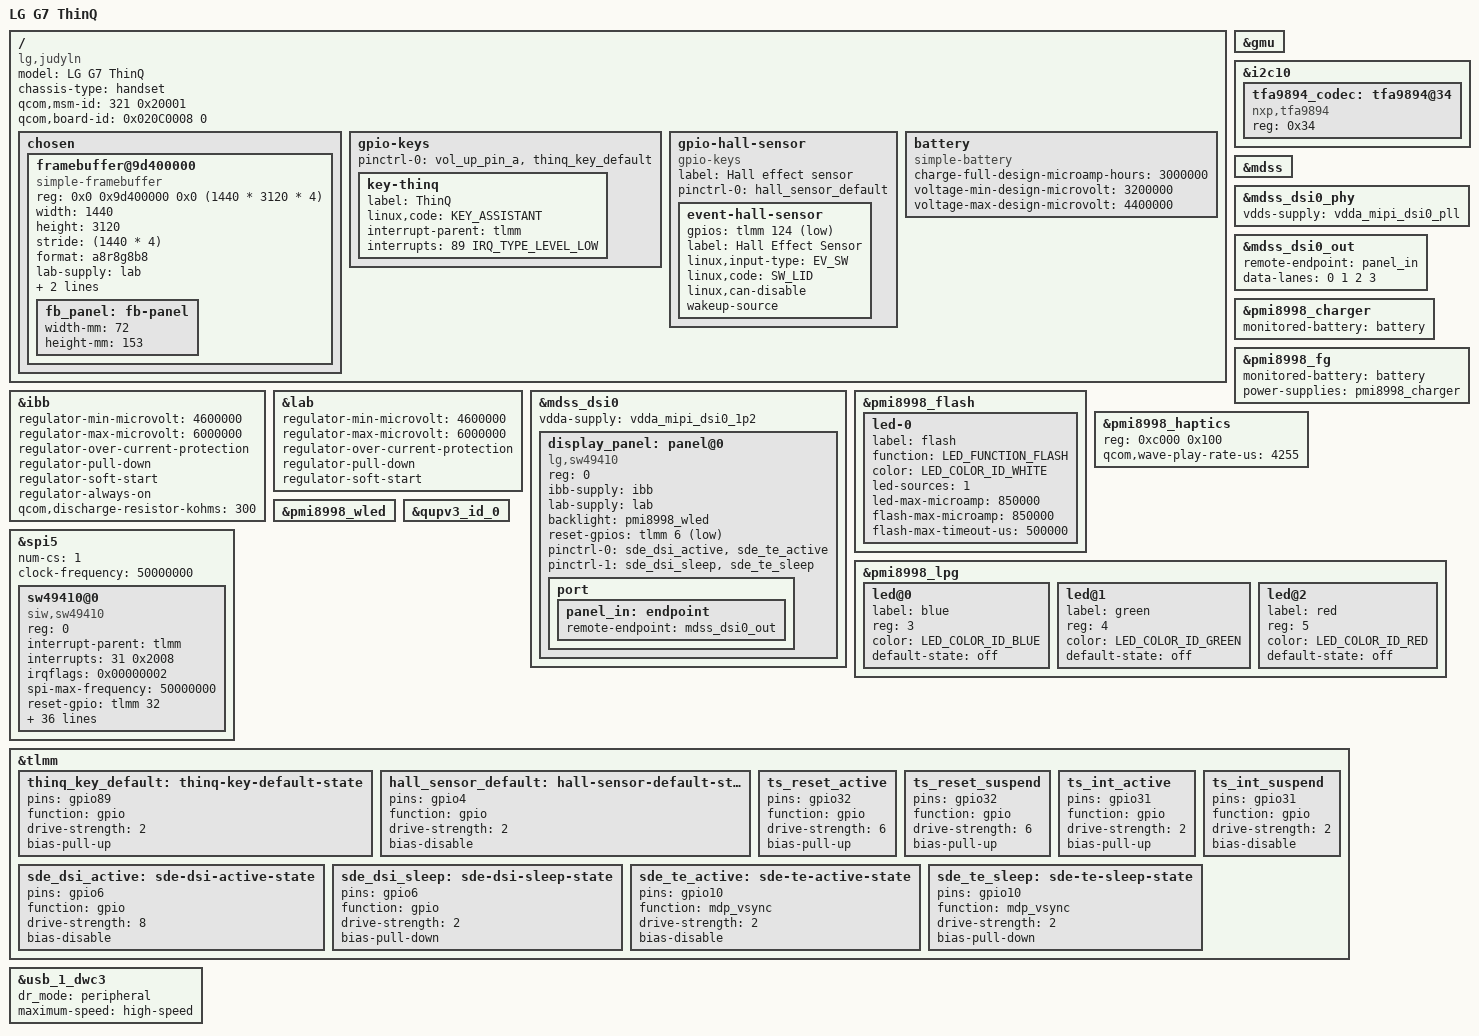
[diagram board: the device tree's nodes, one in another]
// SPDX-License-Identifier: GPL-2.0
/*
 * SDM845 LG G7 (judyln) device tree.
 *
 * Copyright (c) 2022, The Linux Foundation. All rights reserved.
 */

/dts-v1/;

#include "sdm845-lg-common.dtsi"
#include <dt-bindings/leds/common.h>

/ {
	model = "LG G7 ThinQ";
	compatible = "lg,judyln", "qcom,sdm845";
	chassis-type = "handset";
	qcom,msm-id = <321 0x20001>;
	qcom,board-id = <0x020C0008 0>;

	chosen {
		framebuffer@9d400000 {
			compatible = "simple-framebuffer";
			reg = <0x0 0x9d400000 0x0 (1440 * 3120 * 4)>;
			width = <1440>;
			height = <3120>;
			stride = <(1440 * 4)>;
			format = "a8r8g8b8";
			lab-supply = <&lab>;
			ibb-supply = <&ibb>;

			panel = <&fb_panel>;

			fb_panel: fb-panel {
				width-mm = <72>;
				height-mm = <153>;
			};
		};
	};

	/* Additional ThinQ key */
	gpio-keys {
		pinctrl-0 = <&vol_up_pin_a &thinq_key_default>;

		key-thinq {
			label = "ThinQ";
			linux,code = <KEY_ASSISTANT>;
			interrupt-parent = <&tlmm>;
			interrupts = <89 IRQ_TYPE_LEVEL_LOW>;
		};
	};

	gpio-hall-sensor {
		compatible = "gpio-keys";
		label = "Hall effect sensor";

		pinctrl-0 = <&hall_sensor_default>;
		pinctrl-names = "default";

		event-hall-sensor {
			gpios = <&tlmm 124 GPIO_ACTIVE_LOW>;
			label = "Hall Effect Sensor";
			linux,input-type = <EV_SW>;
			linux,code = <SW_LID>;
			linux,can-disable;
			wakeup-source;
		};
	};

	battery: battery {
		status = "okay";
		compatible = "simple-battery";

		charge-full-design-microamp-hours = <3000000>;
		voltage-min-design-microvolt = <3200000>;
		voltage-max-design-microvolt = <4400000>;
	};
};

&gmu {
	status = "okay";
};

&i2c10 {
	status = "okay";

	tfa9894_codec: tfa9894@34 {
		#sound-dai-cells = <1>;
		compatible = "nxp,tfa9894";
		reg = <0x34>;
	};
};

&ibb {
	regulator-min-microvolt = <4600000>;
	regulator-max-microvolt = <6000000>;
	regulator-over-current-protection;
	regulator-pull-down;
	regulator-soft-start;
	regulator-always-on;
	qcom,discharge-resistor-kohms = <300>;
};

&lab {
	regulator-min-microvolt = <4600000>;
	regulator-max-microvolt = <6000000>;
	regulator-over-current-protection;
	regulator-pull-down;
	regulator-soft-start;
};

&mdss {
	status = "okay";
};

&mdss_dsi0 {
	status = "okay";
	vdda-supply = <&vdda_mipi_dsi0_1p2>;

	display_panel: panel@0 {
		reg = <0>;
		compatible = "lg,sw49410";

		ibb-supply = <&ibb>;
		lab-supply = <&lab>;

		backlight = <&pmi8998_wled>;
		reset-gpios = <&tlmm 6 GPIO_ACTIVE_LOW>;

		pinctrl-names = "default", "sleep";
		pinctrl-0 = <&sde_dsi_active &sde_te_active>;
		pinctrl-1 = <&sde_dsi_sleep &sde_te_sleep>;

		port {
			panel_in: endpoint {
				remote-endpoint = <&mdss_dsi0_out>;
			};
		};
	};
};

&mdss_dsi0_phy {
	status = "okay";
	vdds-supply = <&vdda_mipi_dsi0_pll>;
};

&mdss_dsi0_out {
	remote-endpoint = <&panel_in>;
	data-lanes = <0 1 2 3>;
};

&pmi8998_charger {
	status = "okay";
	monitored-battery = <&battery>;
};

&pmi8998_fg {
	status = "okay";
	monitored-battery = <&battery>;
	power-supplies = <&pmi8998_charger>;
};

&pmi8998_flash {
	status = "okay";

	led-0 {
		label = "flash";
		function = LED_FUNCTION_FLASH;
		color = <LED_COLOR_ID_WHITE>;
		led-sources = <1>;
		led-max-microamp = <850000>;
		flash-max-microamp = <850000>;
		flash-max-timeout-us = <500000>;
	};

};

&pmi8998_haptics {
	status = "okay";
	reg = <0xc000 0x100>;

	qcom,wave-play-rate-us = <4255>;
};

&pmi8998_lpg {
	status = "okay";

	led@0 {
		label = "blue";
		reg = <3>;
		color = <LED_COLOR_ID_BLUE>;
		default-state = "off";
	};

	led@1 {
		label = "green";
		reg = <4>;
		color = <LED_COLOR_ID_GREEN>;
		default-state = "off";
	};

	led@2 {
		label = "red";
		reg = <5>;
		color = <LED_COLOR_ID_RED>;
		default-state = "off";
	};
};

&pmi8998_wled {
	status = "okay";
};

&qupv3_id_0 {
	status = "okay";
};

&spi5 {
	status = "okay";

	num-cs = <1>;
	clock-frequency = <50000000>;

	sw49410@0 {
		compatible = "siw,sw49410";
		reg = <0>;
		status = "okay";
		interrupt-parent = <&tlmm>;
		interrupts = <31 0x2008>;
		irqflags = <0x00000002>;
		spi-max-frequency = <50000000>;

		reset-gpio = <&tlmm 32 0x00>;
		irq-gpio = <&tlmm 31 0x2008>;

		/* caps */
		max_x = <1439>;
		max_y = <3119>;
		max_pressure = <0xff>;
		max_width_major = <1439>;
		max_width_minor = <3119>;
		max_orientation = <90>;
		max_id = <10>;
		hw_reset_delay = <90>;
		sw_reset_delay = <10>;

		/* role */
		use_lpwg = <1>;
		use_lpwg_test = <1>;
		hide_coordinate = <1>;

		/* firmware */
		fw_image = "touch/judyln/SW49410_L0W60NEO_1_07.img";

		panel_spec = "touch/judyln/judyln_limit.txt";
		panel_spec_mfts_folder = "touch/judyln/judyln_limit_mfts.txt";

		/* asc */
		use_asc = <0>;
		low_delta_thres = <350>;
		high_delta_thres = <600>;
		max_delta_cnt = <2>;

		/* Performance Test */
		use_perf_test = <1>;
		test_delay = <8>;
		test_pressure = <50>;
		test_width = <100>;
		click_test_x = <180>;
		click_test_y = <760>;
		v_drag_test_x = <144>;
		v_drag_test_start_y = <2003>;
		v_drag_test_end_y = <1116>;
		h_drag_test_start_x = <1163>;
		h_drag_test_end_x = <276>;
		h_drag_test_y = <2184>;

		pinctrl-names = "touch_pin_active", "touch_pin_sleep";
		pinctrl-0 = <&ts_reset_active &ts_int_active>;
		pinctrl-1 = <&ts_reset_suspend &ts_int_suspend>;
	};
};


&tlmm {
	thinq_key_default: thinq-key-default-state {
		pins = "gpio89";
		function = "gpio";

		drive-strength = <2>;
		bias-pull-up;
	};

	hall_sensor_default: hall-sensor-default-state {
		pins = "gpio4";
		function = "gpio";

		drive-strength = <2>;
		bias-disable;
	};

    ts_reset_active: ts_reset_active {
        pins = "gpio32";
        function = "gpio";
        drive-strength = <6>;
        bias-pull-up;
    };

    ts_reset_suspend: ts_reset_suspend {
        pins = "gpio32";
        function = "gpio";
        drive-strength = <6>;
        bias-pull-up;
    };

    ts_int_active: ts_int_active {
        pins = "gpio31";
        function = "gpio";
        drive-strength = <2>;
        bias-pull-up;
    };

    ts_int_suspend: ts_int_suspend {
        pins = "gpio31";
        function = "gpio";
        drive-strength = <2>;
        bias-disable;
    };

	sde_dsi_active: sde-dsi-active-state {
		pins = "gpio6";
		function = "gpio";
		drive-strength = <8>;
		bias-disable;
	};

	sde_dsi_sleep: sde-dsi-sleep-state {
		pins = "gpio6";
		function = "gpio";
		drive-strength = <2>;
		bias-pull-down;
	};

	sde_te_active: sde-te-active-state {
		pins = "gpio10";
		function = "mdp_vsync";
		drive-strength = <2>;
		bias-disable;
	};

	sde_te_sleep: sde-te-sleep-state {
		pins = "gpio10";
		function = "mdp_vsync";
		drive-strength = <2>;
		bias-pull-down;
	};
};

&usb_1_dwc3 {
	dr_mode = "peripheral";
	maximum-speed = "high-speed";
};
